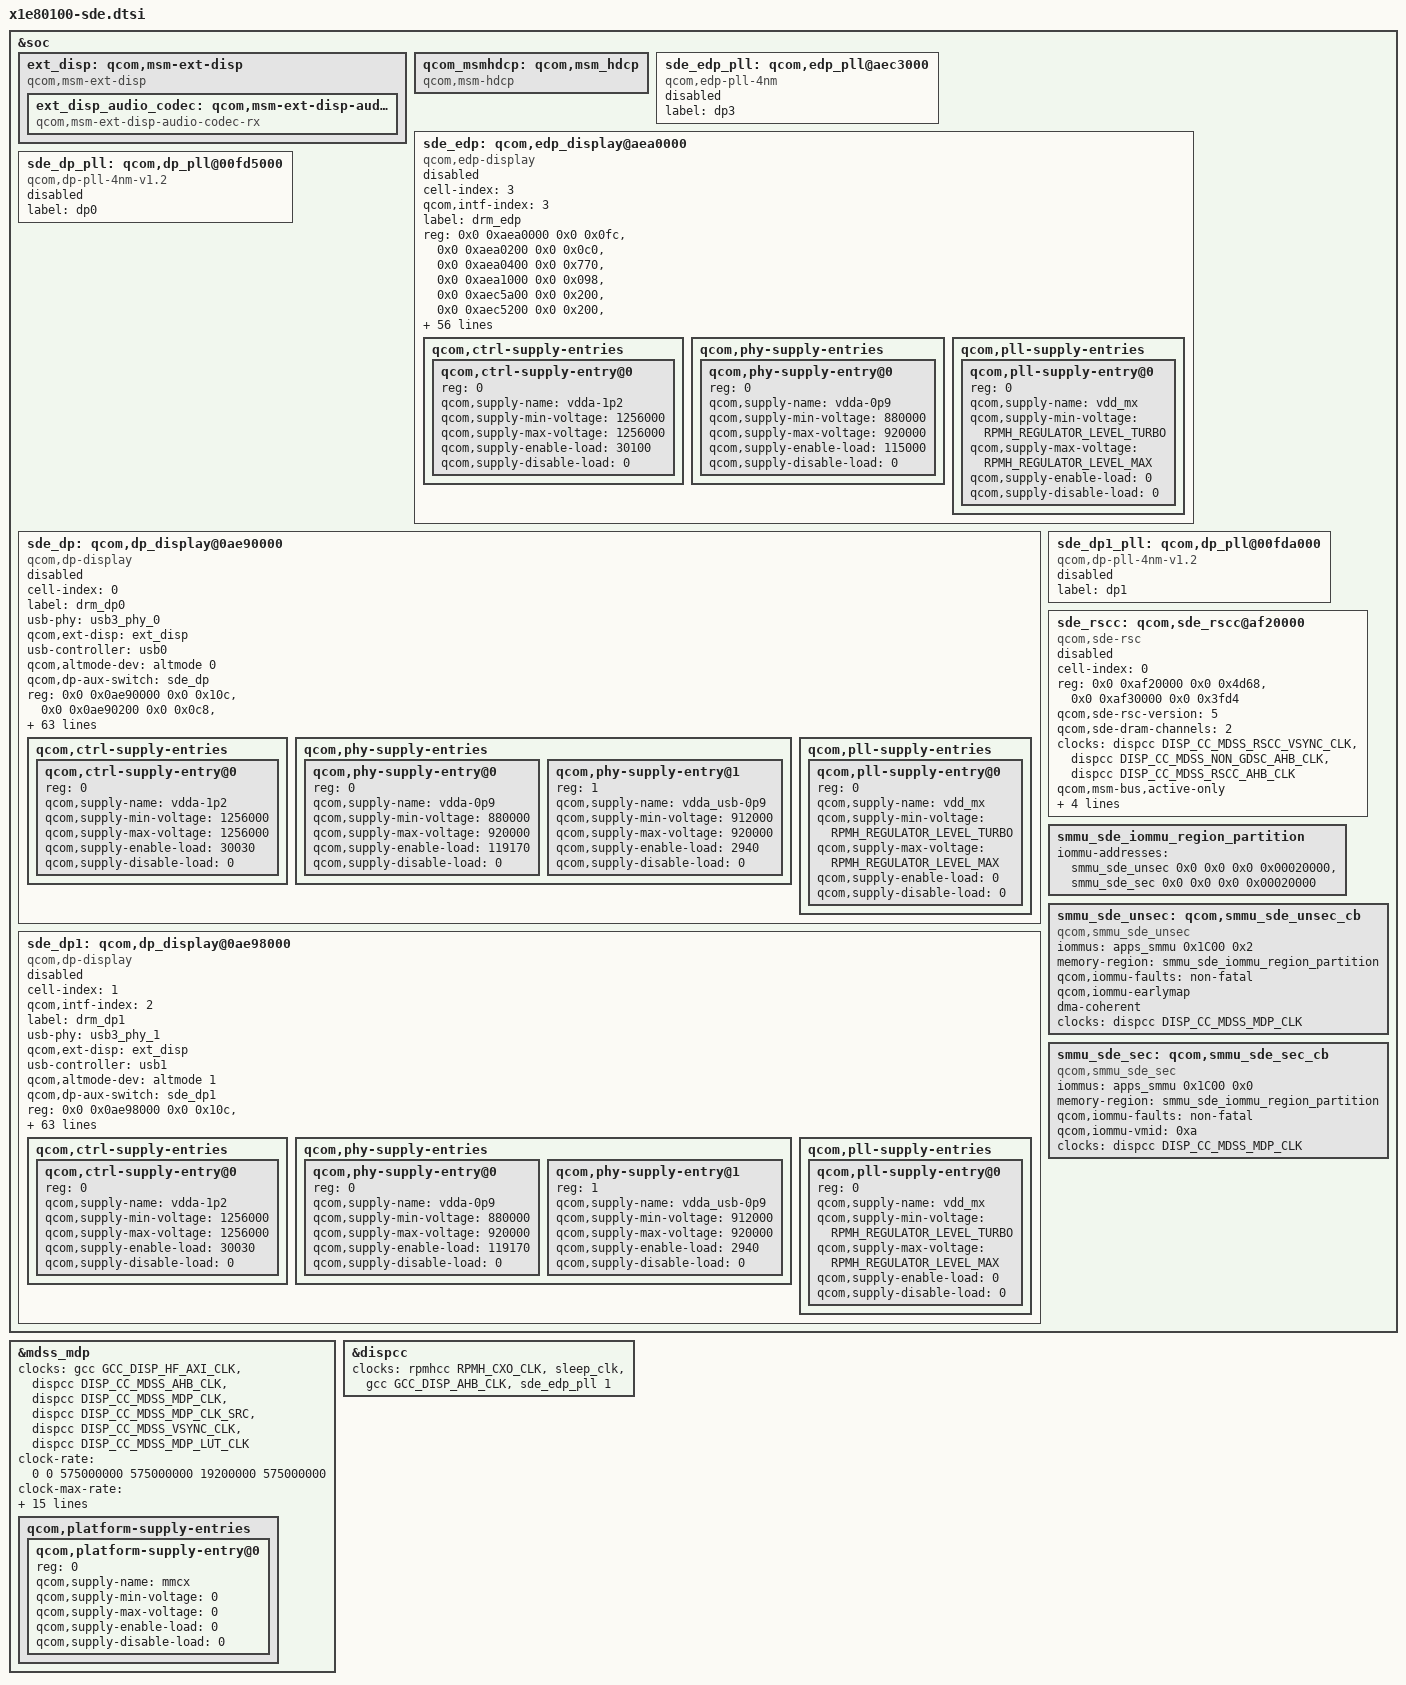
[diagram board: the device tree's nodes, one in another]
// SPDX-License-Identifier: BSD-3-Clause-Clear
/*
 * Copyright (c) Qualcomm Technologies, Inc. and/or its subsidiaries.
 */

#include <dt-bindings/regulator/qcom,rpmh-regulator-levels.h>
#include <dt-bindings/clock/qcom,x1e80100-dispcc.h>
#include <dt-bindings/clock/qcom,x1e80100-gcc.h>
#include <dt-bindings/clock/qcom,x1e80100-tcsr.h>
#include <dt-bindings/interconnect/qcom,x1e80100-rpmh.h>
#include <dt-bindings/clock/qcom,rpmh.h>
#include "x1e80100-sde-common.dtsi"

&soc {
	ext_disp: qcom,msm-ext-disp {
		compatible = "qcom,msm-ext-disp";

		ext_disp_audio_codec: qcom,msm-ext-disp-audio-codec-rx {
			compatible = "qcom,msm-ext-disp-audio-codec-rx";
		};
	};

	qcom_msmhdcp: qcom,msm_hdcp {
		compatible = "qcom,msm-hdcp";
	};

	sde_edp_pll: qcom,edp_pll@aec3000 {
		status = "disabled";
		compatible = "qcom,edp-pll-4nm";
		label = "dp3";
		#clock-cells = <1>;
	};

	sde_edp: qcom,edp_display@aea0000 {
		status = "disabled";
		cell-index = <3>;
		qcom,intf-index = <3>;
		compatible = "qcom,edp-display";
		label = "drm_edp";

		reg =   <0x0 0xaea0000 0x0 0x0fc>,
			<0x0 0xaea0200 0x0 0x0c0>,
			<0x0 0xaea0400 0x0 0x770>,
			<0x0 0xaea1000 0x0 0x098>,
			<0x0 0xaec5a00 0x0 0x200>,
			<0x0 0xaec5200 0x0 0x200>,
			<0x0 0xaec5600 0x0 0x200>,
			<0x0 0xaf082a0 0x0 0x1f>,
			<0x0 0xaec5000 0x0 0x200>,
			<0x0 0xaee4000 0x0 0x034>,
			<0x0 0xaf09000 0x0 0x14>;
		reg-names = "dp_ahb", "dp_aux", "dp_link",
			"dp_p0", "dp_phy", "dp_ln_tx0", "dp_ln_tx1",
			"dp_mmss_cc", "dp_pll",
			"hdcp_physical", "gdsc";

		qcom,pixel-base-off = <0>;
		interrupt-parent = <&mdss_mdp>;
		interrupts = <15 0>;

		qcom,dp-aux-switch = <&sde_edp>;

		#clock-cells = <1>;
		clocks =  <&dispcc DISP_CC_MDSS_DPTX3_AUX_CLK>,
			<&rpmhcc RPMH_CXO_CLK>,
			<&tcsrcc TCSR_EDP_CLKREF_EN>,
			<&dispcc DISP_CC_MDSS_DPTX3_LINK_CLK>,
			<&dispcc DISP_CC_MDSS_DPTX3_LINK_CLK_SRC>,
			<&dispcc DISP_CC_MDSS_DPTX3_LINK_INTF_CLK>,
			<&sde_edp_pll 0>,
			<&dispcc DISP_CC_MDSS_DPTX3_PIXEL0_CLK_SRC>,
			<&sde_edp_pll 1>,
			<&rpmhcc RPMH_CXO_CLK>,
			<&dispcc DISP_CC_MDSS_DPTX3_PIXEL0_CLK>;

		clock-names = "core_aux_clk", "rpmh_cxo_clk", "core_edp_refclk",
			"link_clk", "link_clk_src", "link_iface_clk",
			"link_parent",
			"pixel_clk_rcg", "pixel_parent",
			"pixel1_clk_rcg",
			"strm0_pixel_clk";

		qcom,dp-pll = <&sde_edp_pll>;
		qcom,phy-version = <0x500>;
		qcom,phy-revision = "v2";
		qcom,phy-mode = "edp";
		qcom,aux-cfg0-settings = [24 00];
		//qcom,aux-cfg1-settings = [28 13];
		qcom,aux-cfg1-settings = [28 00];
		qcom,aux-cfg2-settings = [2c A4];
		qcom,aux-cfg3-settings = [30 00];
		qcom,aux-cfg4-settings = [34 0a];
		qcom,aux-cfg5-settings = [38 26];
		qcom,aux-cfg6-settings = [3c 0a];
		qcom,aux-cfg7-settings = [40 03];
		qcom,aux-cfg8-settings = [44 37];
		qcom,aux-cfg9-settings = [48 03];

		qcom,max-pclk-frequency-khz = <675000>;
		qcom,display-type = "primary";

		qcom,widebus-enable;
		qcom,4ppc-enable;
		qcom,dsc-feature-enable;
		qcom,fec-feature-enable;

		qcom,qos-cpu-mask = <0xf>;
		qcom,qos-cpu-latency-us = <300>;

		vdda-1p2-supply = <&L2J>;
		vdda-0p9-supply = <&L3J>;
		vdd_mx-supply = <&VDD_MXA_LEVEL>;

		qcom,hbr-rbr-voltage-swing = <0x07 0x0f 0x16 0x1f>,
					<0x0d 0x16 0x1e 0xff>,
					<0x11 0x1b 0xff 0xff>,
					<0x16 0xff 0xff 0xff>;
		qcom,hbr-rbr-pre-emphasis = <0x05 0x11 0x17 0x1d>,
					<0x05 0x11 0x18 0xff>,
					<0x06 0x11 0xff 0xff>,
					<0x00 0xff 0xff 0xff>;

		qcom,hbr2-3-voltage-swing = <0x0b 0x11 0x17 0x1c>,
					<0x10 0x19 0x1f 0xff>,
					<0x19 0x1f 0xff 0xff>,
					<0x1f 0xff 0xff 0xff>;
		qcom,hbr2-3-pre-emphasis = <0x0c 0x15 0x19 0x1e>,
					<0x0b 0x15 0x19 0xff>,
					<0x0e 0x14 0xff 0xff>,
					<0x0d 0xff 0xff 0xff>;

		qcom,ctrl-supply-entries {
			#address-cells = <1>;
			#size-cells = <0>;

			qcom,ctrl-supply-entry@0 {
				reg = <0>;
				qcom,supply-name = "vdda-1p2";
				qcom,supply-min-voltage = <1256000>;
				qcom,supply-max-voltage = <1256000>;
				qcom,supply-enable-load = <30100>;
				qcom,supply-disable-load = <0>;
			};
		};

		qcom,phy-supply-entries {
			#address-cells = <1>;
			#size-cells = <0>;

			qcom,phy-supply-entry@0 {
				reg = <0>;
				qcom,supply-name = "vdda-0p9";
				qcom,supply-min-voltage = <880000>;
				qcom,supply-max-voltage = <920000>;
				qcom,supply-enable-load = <115000>;
				qcom,supply-disable-load = <0>;
			};
		};

		qcom,pll-supply-entries {
			#address-cells = <1>;
			#size-cells = <0>;

			qcom,pll-supply-entry@0 {
				reg = <0>;
				qcom,supply-name = "vdd_mx";
				qcom,supply-min-voltage =
						<RPMH_REGULATOR_LEVEL_TURBO>;
				qcom,supply-max-voltage =
						<RPMH_REGULATOR_LEVEL_MAX>;
				qcom,supply-enable-load = <0>;
				qcom,supply-disable-load = <0>;
			};
		};
	};

	sde_dp_pll: qcom,dp_pll@00fd5000 {
		status = "disabled";
		compatible = "qcom,dp-pll-4nm-v1.2";
		label = "dp0";
		#clock-cells = <1>;
	};

	sde_dp: qcom,dp_display@0ae90000 {
		status = "disabled";
		cell-index = <0>;
		compatible = "qcom,dp-display";
		label = "drm_dp0";

		usb-phy = <&usb3_phy_0>;
		qcom,ext-disp = <&ext_disp>;
		usb-controller = <&usb0>;
		qcom,altmode-dev = <&altmode 0>;
		qcom,dp-aux-switch  = <&sde_dp>;

		reg =   <0x0 0x0ae90000 0x0 0x10c>,
			<0x0 0x0ae90200 0x0 0x0c8>,
			<0x0 0x0ae90400 0x0 0xb78>,
			<0x0 0x0ae91000 0x0 0x0a0>,
			<0x0 0x00fd7200 0x0 0x200>,
			<0x0 0x00fd5400 0x0 0x200>,
			<0x0 0x00fd5a00 0x0 0x200>,
			<0x0 0x00fd7000 0x0 0x200>,
			<0x0 0x00fd5000 0x0 0x020>,
			<0x0 0x0aee1000 0x0 0x034>,
			<0x0 0x0ae91400 0x0 0x0a0>,
			<0x0 0xaf09000 0x0 0x014>;
		reg-names = "dp_ahb", "dp_aux", "dp_link",
			"dp_p0", "dp_phy", "dp_ln_tx0", "dp_ln_tx1",
			"dp_pll", "usb3_dp_com", "hdcp_physical",
			"dp_p1", "gdsc";

		interrupt-parent = <&mdss_mdp>;
		interrupts = <12 0>;

		#clock-cells = <1>;
		clocks =  <&dispcc DISP_CC_MDSS_DPTX0_AUX_CLK>,
			<&rpmhcc RPMH_CXO_CLK>,
			<&tcsrcc TCSR_USB4_1_CLKREF_EN>,
			<&gcc GCC_USB3_PRIM_PHY_PIPE_CLK>,
			<&dispcc DISP_CC_MDSS_DPTX0_LINK_CLK>,
			<&dispcc DISP_CC_MDSS_DPTX0_LINK_CLK_SRC>,
			<&sde_dp_pll 0>,
			<&dispcc DISP_CC_MDSS_DPTX0_LINK_INTF_CLK>,
			<&dispcc DISP_CC_MDSS_DPTX0_PIXEL0_CLK_SRC>,
			<&sde_dp_pll 1>,
			<&dispcc DISP_CC_MDSS_DPTX0_PIXEL1_CLK_SRC>,
			<&dispcc DISP_CC_MDSS_DPTX0_PIXEL0_CLK>,
			<&dispcc DISP_CC_MDSS_DPTX0_PIXEL1_CLK>;
		clock-names = "core_aux_clk", "rpmh_cxo_clk", "core_usb_ref_clk_src",
			"core_usb_pipe_clk", "link_clk", "link_clk_src", "link_parent",
			"link_iface_clk", "pixel_clk_rcg", "pixel_parent",
			"pixel1_clk_rcg", "strm0_pixel_clk", "strm1_pixel_clk";

		qcom,dp-pll = <&sde_dp_pll>;
		qcom,phy-version = <0x600>;
		qcom,phy-revision = "v2";
		qcom,aux-cfg0-settings = [20 00];
		qcom,aux-cfg1-settings = [24 13];
		qcom,aux-cfg2-settings = [28 A4];
		qcom,aux-cfg3-settings = [2c 00];
		qcom,aux-cfg4-settings = [30 0a];
		qcom,aux-cfg5-settings = [34 26];
		qcom,aux-cfg6-settings = [38 0a];
		qcom,aux-cfg7-settings = [3c 03];
		qcom,aux-cfg8-settings = [40 b7];
		qcom,aux-cfg9-settings = [44 03];

		qcom,max-pclk-frequency-khz = <675000>;

		qcom,widebus-enable;
		qcom,4ppc-enable;
		qcom,dsc-feature-enable;
		qcom,fec-feature-enable;
		qcom,dsc-continuous-pps;

		qcom,qos-cpu-mask = <0xf>;
		qcom,qos-cpu-latency-us = <300>;

		vdda-1p2-supply = <&L2J>;
		vdda-0p9-supply = <&L3J>;
		vdda_usb-0p9-supply = <&L1J>;
		vdd_mx-supply = <&VDD_MXA_LEVEL>;
		power-domains = <&gcc GCC_USB_0_PHY_GDSC>;

		qcom,hbr-rbr-voltage-swing = <0x07 0x0f 0x16 0x1f>,
					<0x11 0x1e 0x1f 0xff>,
					<0x16 0x1f 0xff 0xff>,
					<0x1f 0xff 0xff 0xff>;
		qcom,hbr-rbr-pre-emphasis = <0x00 0x0d 0x14 0x1a>,
					<0x00 0x0e 0x15 0xff>,
					<0x00 0x0e 0xff 0xff>,
					<0x02 0xff 0xff 0xff>;

		qcom,hbr2-3-voltage-swing = <0x02 0x12 0x16 0x1a>,
					<0x09 0x19 0x1f 0xff>,
					<0x10 0x1f 0xff 0xff>,
					<0x1f 0xff 0xff 0xff>;
		qcom,hbr2-3-pre-emphasis = <0x00 0x0c 0x15 0x1b>,
					<0x02 0x0e 0x16 0xff>,
					<0x02 0x11 0xff 0xff>,
					<0x04 0xff 0xff 0xff>;

		qcom,ctrl-supply-entries {
			#address-cells = <1>;
			#size-cells = <0>;

			qcom,ctrl-supply-entry@0 {
				reg = <0>;
				qcom,supply-name = "vdda-1p2";
				qcom,supply-min-voltage = <1256000>;
				qcom,supply-max-voltage = <1256000>;
				qcom,supply-enable-load = <30030>;
				qcom,supply-disable-load = <0>;
			};
		};

		qcom,phy-supply-entries {
			#address-cells = <1>;
			#size-cells = <0>;

			qcom,phy-supply-entry@0 {
				reg = <0>;
				qcom,supply-name = "vdda-0p9";
				qcom,supply-min-voltage = <880000>;
				qcom,supply-max-voltage = <920000>;
				qcom,supply-enable-load = <119170>;
				qcom,supply-disable-load = <0>;
			};

			qcom,phy-supply-entry@1 {
				reg = <1>;
				qcom,supply-name = "vdda_usb-0p9";
				qcom,supply-min-voltage = <912000>;
				qcom,supply-max-voltage = <920000>;
				qcom,supply-enable-load = <2940>;
				qcom,supply-disable-load = <0>;
			};
		};

		qcom,pll-supply-entries {
			#address-cells = <1>;
			#size-cells = <0>;

			qcom,pll-supply-entry@0 {
				reg = <0>;
				qcom,supply-name = "vdd_mx";
				qcom,supply-min-voltage =
						<RPMH_REGULATOR_LEVEL_TURBO>;
				qcom,supply-max-voltage =
						<RPMH_REGULATOR_LEVEL_MAX>;
				qcom,supply-enable-load = <0>;
				qcom,supply-disable-load = <0>;
			};
		};
	};

	sde_dp1_pll: qcom,dp_pll@00fda000 {
		status = "disabled";
		compatible = "qcom,dp-pll-4nm-v1.2";
		label = "dp1";
		#clock-cells = <1>;
	};

	sde_dp1: qcom,dp_display@0ae98000 {
		status = "disabled";
		cell-index = <1>;
		qcom,intf-index = <2>;
		compatible = "qcom,dp-display";
		label = "drm_dp1";

		usb-phy = <&usb3_phy_1>;
		qcom,ext-disp = <&ext_disp>;
		usb-controller = <&usb1>;
		qcom,altmode-dev = <&altmode 1>;
		qcom,dp-aux-switch  = <&sde_dp1>;

		reg =   <0x0 0x0ae98000 0x0 0x10c>,
			<0x0 0x0ae98200 0x0 0x0c8>,
			<0x0 0x0ae98400 0x0 0xb78>,
			<0x0 0x0ae99000 0x0 0x0a0>,
			<0x0 0x00fdc200 0x0 0x200>,
			<0x0 0x00fda400 0x0 0x200>,
			<0x0 0x00fdaa00 0x0 0x200>,
			<0x0 0x00fdc000 0x0 0x200>,
			<0x0 0x00fda000 0x0 0x020>,
			<0x0 0x0aee2000 0x0 0x034>,
			<0x0 0x0ae99400 0x0 0x0a0>,
			<0x0 0xaf09000 0x0 0x014>;
		reg-names = "dp_ahb", "dp_aux", "dp_link",
			"dp_p0", "dp_phy", "dp_ln_tx0", "dp_ln_tx1",
			"dp_pll", "usb3_dp_com", "hdcp_physical",
			"dp_p1", "gdsc";

		interrupt-parent = <&mdss_mdp>;
		interrupts = <13 0>;

		#clock-cells = <1>;
		clocks =  <&dispcc DISP_CC_MDSS_DPTX1_AUX_CLK>,
			<&rpmhcc RPMH_CXO_CLK>,
			<&tcsrcc TCSR_USB4_2_CLKREF_EN>,
			<&gcc GCC_USB3_SEC_PHY_PIPE_CLK>,
			<&dispcc DISP_CC_MDSS_DPTX1_LINK_CLK>,
			<&dispcc DISP_CC_MDSS_DPTX1_LINK_CLK_SRC>,
			<&sde_dp1_pll 0>,
			<&dispcc DISP_CC_MDSS_DPTX1_LINK_INTF_CLK>,
			<&dispcc DISP_CC_MDSS_DPTX1_PIXEL0_CLK_SRC>,
			<&sde_dp1_pll 1>,
			<&dispcc DISP_CC_MDSS_DPTX1_PIXEL1_CLK_SRC>,
			<&dispcc DISP_CC_MDSS_DPTX1_PIXEL0_CLK>,
			<&dispcc DISP_CC_MDSS_DPTX1_PIXEL1_CLK>;
		clock-names = "core_aux_clk", "rpmh_cxo_clk", "core_usb_ref_clk_src",
			"core_usb_pipe_clk", "link_clk", "link_clk_src", "link_parent",
			"link_iface_clk", "pixel_clk_rcg", "pixel_parent",
			"pixel1_clk_rcg", "strm0_pixel_clk", "strm1_pixel_clk";

		qcom,dp-pll = <&sde_dp1_pll>;
		qcom,phy-version = <0x600>;
		qcom,phy-revision = "v2";
		qcom,aux-cfg0-settings = [20 00];
		qcom,aux-cfg1-settings = [24 13];
		qcom,aux-cfg2-settings = [28 A4];
		qcom,aux-cfg3-settings = [2c 00];
		qcom,aux-cfg4-settings = [30 0a];
		qcom,aux-cfg5-settings = [34 26];
		qcom,aux-cfg6-settings = [38 0a];
		qcom,aux-cfg7-settings = [3c 03];
		qcom,aux-cfg8-settings = [40 b7];
		qcom,aux-cfg9-settings = [44 03];

		qcom,max-pclk-frequency-khz = <675000>;

		qcom,widebus-enable;
		qcom,4ppc-enable;
		qcom,dsc-feature-enable;
		qcom,fec-feature-enable;
		qcom,dsc-continuous-pps;

		qcom,qos-cpu-mask = <0xf>;
		qcom,qos-cpu-latency-us = <300>;

		vdda-1p2-supply = <&L2J>;
		vdda-0p9-supply = <&L3J>;
		vdda_usb-0p9-supply = <&L2D>;
		vdd_mx-supply = <&VDD_MXA_LEVEL>;

		qcom,hbr-rbr-voltage-swing = <0x07 0x0f 0x16 0x1f>,
					<0x11 0x1e 0x1f 0xff>,
					<0x16 0x1f 0xff 0xff>,
					<0x1f 0xff 0xff 0xff>;
		qcom,hbr-rbr-pre-emphasis = <0x00 0x0d 0x14 0x1a>,
					<0x00 0x0e 0x15 0xff>,
					<0x00 0x0e 0xff 0xff>,
					<0x02 0xff 0xff 0xff>;

		qcom,hbr2-3-voltage-swing = <0x02 0x12 0x16 0x1a>,
					<0x09 0x19 0x1f 0xff>,
					<0x10 0x1f 0xff 0xff>,
					<0x1f 0xff 0xff 0xff>;
		qcom,hbr2-3-pre-emphasis = <0x00 0x0c 0x15 0x1b>,
					<0x02 0x0e 0x16 0xff>,
					<0x02 0x11 0xff 0xff>,
					<0x04 0xff 0xff 0xff>;

		qcom,ctrl-supply-entries {
			#address-cells = <1>;
			#size-cells = <0>;

			qcom,ctrl-supply-entry@0 {
				reg = <0>;
				qcom,supply-name = "vdda-1p2";
				qcom,supply-min-voltage = <1256000>;
				qcom,supply-max-voltage = <1256000>;
				qcom,supply-enable-load = <30030>;
				qcom,supply-disable-load = <0>;
			};
		};

		qcom,phy-supply-entries {
			#address-cells = <1>;
			#size-cells = <0>;

			qcom,phy-supply-entry@0 {
				reg = <0>;
				qcom,supply-name = "vdda-0p9";
				qcom,supply-min-voltage = <880000>;
				qcom,supply-max-voltage = <920000>;
				qcom,supply-enable-load = <119170>;
				qcom,supply-disable-load = <0>;
			};

			qcom,phy-supply-entry@1 {
				reg = <1>;
				qcom,supply-name = "vdda_usb-0p9";
				qcom,supply-min-voltage = <912000>;
				qcom,supply-max-voltage = <920000>;
				qcom,supply-enable-load = <2940>;
				qcom,supply-disable-load = <0>;
			};
		};

		qcom,pll-supply-entries {
			#address-cells = <1>;
			#size-cells = <0>;

			qcom,pll-supply-entry@0 {
				reg = <0>;
				qcom,supply-name = "vdd_mx";
				qcom,supply-min-voltage =
						<RPMH_REGULATOR_LEVEL_TURBO>;
				qcom,supply-max-voltage =
						<RPMH_REGULATOR_LEVEL_MAX>;
				qcom,supply-enable-load = <0>;
				qcom,supply-disable-load = <0>;
			};
		};
	};

	sde_rscc: qcom,sde_rscc@af20000 {
		status = "disabled";
		cell-index = <0>;
		compatible = "qcom,sde-rsc";
		reg = <0x0 0xaf20000 0x0 0x4d68>,
			<0x0 0xaf30000 0x0 0x3fd4>;
		reg-names = "drv", "wrapper";
		qcom,sde-rsc-version = <5>;

		qcom,sde-dram-channels = <2>;


		clocks = <&dispcc DISP_CC_MDSS_RSCC_VSYNC_CLK>,
			<&dispcc DISP_CC_MDSS_NON_GDSC_AHB_CLK>,
			<&dispcc DISP_CC_MDSS_RSCC_AHB_CLK>;
		clock-names = "vsync_clk", "gdsc_clk", "iface_clk";

		qcom,msm-bus,active-only;
		interconnects =
			<&mmss_noc MASTER_MDP_DISP &mc_virt SLAVE_EBI1_DISP>;
		interconnect-names = "qcom,sde-data-bus0";

		power-domains = <&dispcc DISP_CC_MDSS_CORE_GDSC>, <&dispcc DISP_CC_MDSS_CORE_INT2_GDSC>;
		power-domain-names = "core_gdsc", "core_int2_gdsc";
	};

	smmu_sde_iommu_region_partition: smmu_sde_iommu_region_partition {
		iommu-addresses = <&smmu_sde_unsec 0x0 0x0 0x0 0x00020000>,
				<&smmu_sde_sec 0x0 0x0 0x0 0x00020000>;
	};

	smmu_sde_unsec: qcom,smmu_sde_unsec_cb {
		compatible = "qcom,smmu_sde_unsec";
		iommus = <&apps_smmu 0x1C00 0x2>;
		memory-region = <&smmu_sde_iommu_region_partition>;
		qcom,iommu-faults = "non-fatal";
		qcom,iommu-earlymap;
		dma-coherent;
		clocks = <&dispcc DISP_CC_MDSS_MDP_CLK>;
		clock-names = "mdp_core_clk";
	};

	smmu_sde_sec: qcom,smmu_sde_sec_cb {
		compatible = "qcom,smmu_sde_sec";
		iommus = <&apps_smmu 0x1C00 0x0>;
		memory-region = <&smmu_sde_iommu_region_partition>;
		qcom,iommu-faults = "non-fatal";
		qcom,iommu-vmid = <0xa>;
		clocks = <&dispcc DISP_CC_MDSS_MDP_CLK>;
		clock-names = "mdp_core_clk";
	};
};

&mdss_mdp {
	clocks =
		<&gcc GCC_DISP_HF_AXI_CLK>,
		<&dispcc DISP_CC_MDSS_AHB_CLK>,
		<&dispcc DISP_CC_MDSS_MDP_CLK>,
		<&dispcc DISP_CC_MDSS_MDP_CLK_SRC>,
		<&dispcc DISP_CC_MDSS_VSYNC_CLK>,
		<&dispcc DISP_CC_MDSS_MDP_LUT_CLK>;
	clock-names = "gcc_bus", "iface_clk", "branch_clk",
			 "core_clk", "vsync_clk", "lut_clk";
	clock-rate = <0 0 575000000 575000000 19200000 575000000>;
	clock-max-rate = <0 0 575000000 575000000 19200000 575000000>;

	//clock-mmrm = <0 0 0 0 DISP_CC_MDSS_MDP_CLK_SRC 0 0>;

	mmcx-supply = <&VDD_MMCX_LEVEL>;

	qcom,sde-vm-exclude-reg-names = "ipcc_reg";

	/* data and reg bus scale settings */
	interconnects = <&mmss_noc MASTER_MDP &gem_noc SLAVE_LLCC>,
			<&mc_virt MASTER_LLCC &mc_virt SLAVE_EBI1>,
			<&gem_noc MASTER_APPSS_PROC
				&config_noc SLAVE_DISPLAY_CFG>;
	interconnect-names = "qcom,sde-data-bus0",
			"qcom,sde-ebi-bus", "qcom,sde-reg-bus";

	power-domains = <&dispcc DISP_CC_MDSS_CORE_GDSC>, <&dispcc DISP_CC_MDSS_CORE_INT2_GDSC>;
	power-domain-names = "core_gdsc", "core_int2_gdsc";

	qcom,sde-ib-bw-vote = <2500000 0 800000>;
	qcom,sde-has-idle-pc;
	qcom,sde-dspp-ltm-version = <0x00010002>;
	/* offsets are based off dspp 0, 1, 2, and 3 */
	qcom,sde-dspp-ltm-off = <0x15300 0x14300 0x13300 0x12300>;

	qcom,platform-supply-entries {
		#address-cells = <1>;
		#size-cells = <0>;

		qcom,platform-supply-entry@0 {
			reg = <0>;
			qcom,supply-name = "mmcx";
			qcom,supply-min-voltage = <0>;
			qcom,supply-max-voltage = <0>;
			qcom,supply-enable-load = <0>;
			qcom,supply-disable-load = <0>;
		};
	};
};

&dispcc {
	clocks = <&rpmhcc RPMH_CXO_CLK>,
		<&sleep_clk>,
		<&gcc GCC_DISP_AHB_CLK>,
		<&sde_edp_pll 1>;
	clock-names = "bi_tcxo",
		"sleep_clk",
		"iface",
		"dp3_phy_pll_vco_div_clk";
};

